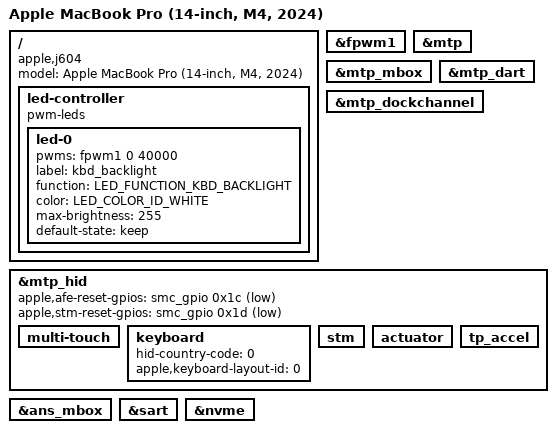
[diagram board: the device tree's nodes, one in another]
// SPDX-License-Identifier: GPL-2.0+ OR MIT
/*
 * Apple MacBook Pro (14-inch, M4, 2024)
 *
 * target-type: J604
 *
 * Copyright The Asahi Linux Contributors
 */

/dts-v1/;

#include "t8132.dtsi"
#include "t8132-jxxx.dtsi"
#include <dt-bindings/gpio/gpio.h>
#include <dt-bindings/leds/common.h>

/ {
	compatible = "apple,j604", "apple,t8132", "apple,arm-platform";
	model = "Apple MacBook Pro (14-inch, M4, 2024)";

	led-controller {
		compatible = "pwm-leds";
		led-0 {
			pwms = <&fpwm1 0 40000>;
			label = "kbd_backlight";
			function = LED_FUNCTION_KBD_BACKLIGHT;
			color = <LED_COLOR_ID_WHITE>;
			max-brightness = <255>;
			default-state = "keep";
		};
	};
};

&fpwm1 {
	status = "okay";
};

&mtp {
	status = "okay";
};

&mtp_mbox {
	status = "okay";
};

&mtp_dart {
	status = "okay";
};

&mtp_dockchannel {
	status = "okay";
};

&mtp_hid {
	apple,afe-reset-gpios = <&smc_gpio 0x1c GPIO_ACTIVE_LOW>;
	apple,stm-reset-gpios = <&smc_gpio 0x1d GPIO_ACTIVE_LOW>;

	multi-touch {
	};

	keyboard: keyboard {
		hid-country-code = <0>;
		apple,keyboard-layout-id = <0>;
	};

	stm {
	};

	actuator {
	};

	tp_accel {
	};
};

&ans_mbox {
	status = "okay";
};

&sart {
	status = "okay";
};

&nvme {
	status = "okay";
};
